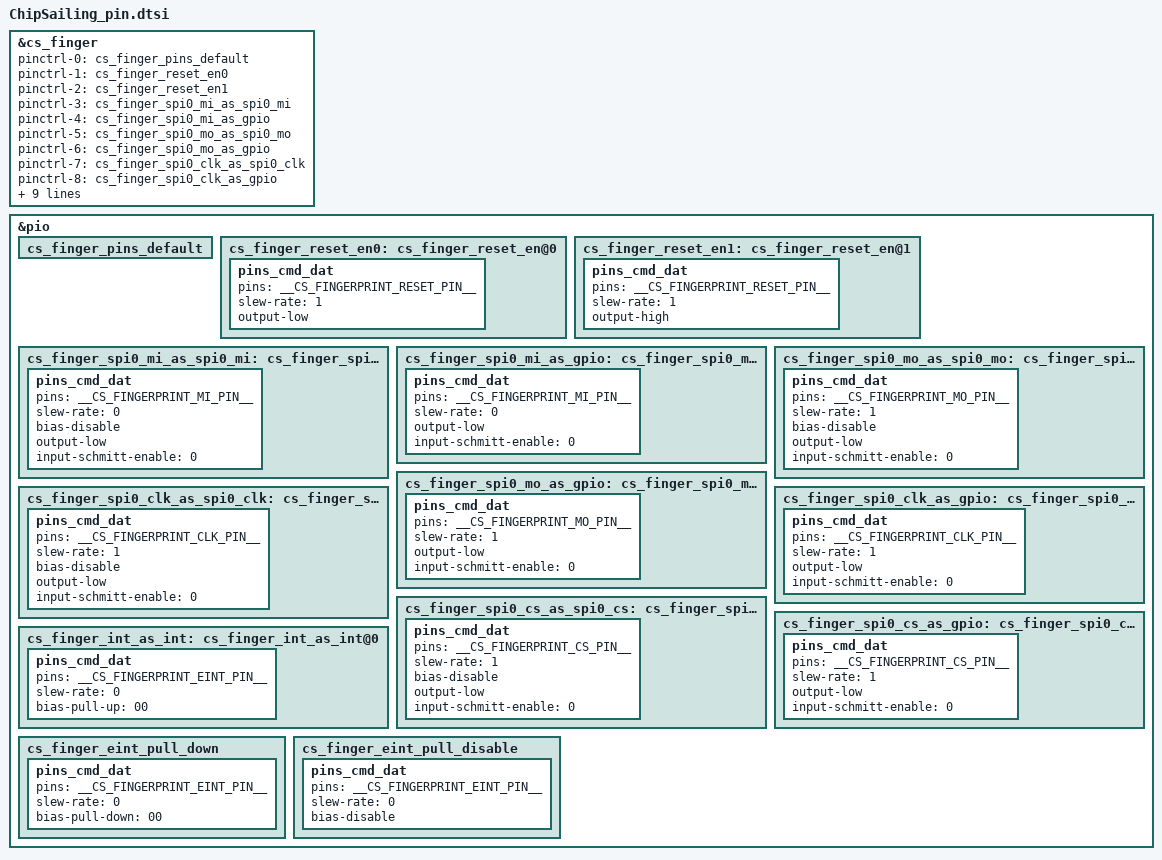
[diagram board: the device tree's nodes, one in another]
/*******************finger pin start ****************/


/*FINGERPRINT GPIO standardization*/
#define __CS_FINGERPRINT_EINT_EN_PIN_NUM__           9
#define __CS_FINGERPRINT_EINT_PIN__                  PINMUX_GPIO9__FUNC_EINT9
#define __CS_FINGERPRINT_RESET_PIN__                 PINMUX_GPIO17__FUNC_GPIO17  
#define __CS_FINGERPRINT_MI_PIN__          			 PINMUX_GPIO3__FUNC_SPI1_MISO   
#define __CS_FINGERPRINT_MO_PIN__     				 PINMUX_GPIO2__FUNC_SPI1_MOSI
#define __CS_FINGERPRINT_CLK_PIN__    				 PINMUX_GPIO1__FUNC_SPI1_SCK  
#define __CS_FINGERPRINT_CS_PIN__    				 PINMUX_GPIO0__FUNC_SPI1_CS  

 
 
&cs_finger{
	pinctrl-names = "cs_finger_pins_default", "cs_finger_reset_en0","cs_finger_reset_en1","cs_finger_spi0_mi_as_spi0_mi","cs_finger_spi0_mi_as_gpio",
                          "cs_finger_spi0_mo_as_spi0_mo","cs_finger_spi0_mo_as_gpio","cs_finger_spi0_clk_as_spi0_clk","cs_finger_spi0_clk_as_gpio","cs_finger_spi0_cs_as_spi0_cs",
                          "cs_finger_spi0_cs_as_gpio","cs_finger_int_as_int","cs_finger_eint_pull_down","cs_finger_eint_pull_disable";
	pinctrl-0 = <&cs_finger_pins_default>;
	pinctrl-1 = <&cs_finger_reset_en0>;
	pinctrl-2 = <&cs_finger_reset_en1>;
	pinctrl-3 = <&cs_finger_spi0_mi_as_spi0_mi>;
	pinctrl-4 = <&cs_finger_spi0_mi_as_gpio>;
	pinctrl-5 = <&cs_finger_spi0_mo_as_spi0_mo>;
	pinctrl-6 = <&cs_finger_spi0_mo_as_gpio>;
	pinctrl-7 = <&cs_finger_spi0_clk_as_spi0_clk>;
	pinctrl-8= <&cs_finger_spi0_clk_as_gpio>;
	pinctrl-9= <&cs_finger_spi0_cs_as_spi0_cs>;
	pinctrl-10= <&cs_finger_spi0_cs_as_gpio>;
	pinctrl-11= <&cs_finger_int_as_int>;
	pinctrl-12= <&cs_finger_eint_pull_down>;
	pinctrl-13= <&cs_finger_eint_pull_disable>;
	interrupt-parent = <&eintc>;
	interrupts = <__CS_FINGERPRINT_EINT_EN_PIN_NUM__ IRQ_TYPE_EDGE_FALLING>;
	debounce = <__CS_FINGERPRINT_EINT_EN_PIN_NUM__ 0>;
	status = "okay";
}; 


/*   GPIO standardization */
&pio {
	cs_finger_pins_default:cs_finger_pins_default{
	};
 
	cs_finger_reset_en0:cs_finger_reset_en@0{
		    pins_cmd_dat {
			pins = <__CS_FINGERPRINT_RESET_PIN__>;
			slew-rate = <1>;
			output-low; 
		};
	};
	cs_finger_reset_en1:cs_finger_reset_en@1{
		    pins_cmd_dat {
			pins = <__CS_FINGERPRINT_RESET_PIN__>;
			slew-rate = <1>;
			output-high;
		};
	};
	cs_finger_spi0_mi_as_spi0_mi:cs_finger_spi0_mi_as_spi0_mi@0{
		    pins_cmd_dat {
			pins = <__CS_FINGERPRINT_MI_PIN__>;
			slew-rate = <0>;
			bias-disable;
			output-low;
			input-schmitt-enable = <0>;
		};
	};
 	
	cs_finger_spi0_mi_as_gpio:cs_finger_spi0_mi_as_gpio@0{
		    pins_cmd_dat {
			pins = <__CS_FINGERPRINT_MI_PIN__>;
			slew-rate = <0>;
			output-low;
			input-schmitt-enable = <0>;
		};
	};
	
 
	cs_finger_spi0_mo_as_spi0_mo:cs_finger_spi0_mo_as_spi0_mo@0{
		    pins_cmd_dat {
			pins = <__CS_FINGERPRINT_MO_PIN__>;
			slew-rate = <1>;
			bias-disable;
			output-low;
			input-schmitt-enable = <0>;
		};
	};
 
	cs_finger_spi0_mo_as_gpio:cs_finger_spi0_mo_as_gpio@0{
		    pins_cmd_dat {
			pins = <__CS_FINGERPRINT_MO_PIN__>;
			slew-rate = <1>;
			output-low;
			input-schmitt-enable = <0>;
		};
	};
	cs_finger_spi0_clk_as_spi0_clk:cs_finger_spi0_clk_as_spi0_clk@0{
		    pins_cmd_dat {
			pins = <__CS_FINGERPRINT_CLK_PIN__>;
			slew-rate = <1>;
			bias-disable;
			output-low;
			input-schmitt-enable = <0>;
		};
	};
	cs_finger_spi0_clk_as_gpio:cs_finger_spi0_clk_as_gpio@0{
		    pins_cmd_dat {
			pins = <__CS_FINGERPRINT_CLK_PIN__>;
			slew-rate = <1>;
			output-low;
			input-schmitt-enable = <0>;
		};
	};
	cs_finger_spi0_cs_as_spi0_cs:cs_finger_spi0_cs_as_spi0_cs@0{
		    pins_cmd_dat {
			pins = <__CS_FINGERPRINT_CS_PIN__>;
			slew-rate = <1>;
			bias-disable;
			output-low;
			input-schmitt-enable = <0>;
		};
	};
	cs_finger_spi0_cs_as_gpio:cs_finger_spi0_cs_as_gpio@0{
		    pins_cmd_dat {
			pins = <__CS_FINGERPRINT_CS_PIN__>;
			slew-rate = <1>;
			output-low;
			input-schmitt-enable = <0>;
		};
	};
	cs_finger_int_as_int: cs_finger_int_as_int@0{
			pins_cmd_dat {
				pins = <__CS_FINGERPRINT_EINT_PIN__>;
				slew-rate = <0>;
				bias-pull-up = <00>;
			};
	};
	
	cs_finger_eint_pull_down: cs_finger_eint_pull_down { 
   pins_cmd_dat { 
     pins = <__CS_FINGERPRINT_EINT_PIN__>; 
     slew-rate = <0>; 
     bias-pull-down = <00>; 
   }; 
 }; 
  cs_finger_eint_pull_disable: cs_finger_eint_pull_disable { 
   pins_cmd_dat { 
     pins = <__CS_FINGERPRINT_EINT_PIN__>; 
     slew-rate = <0>; 
     bias-disable; 
   }; 
 }; 
};
/*******************finger pin end****************/
 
